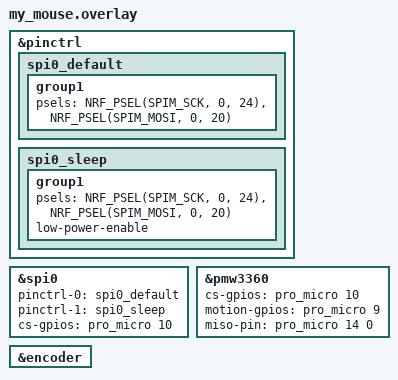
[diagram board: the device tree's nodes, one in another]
#include <dt-bindings/zmk/matrix_transform.h>

&pinctrl {
    spi0_default: spi0_default {
        group1 {
            // D5 (SCK) and D3 (MOSI)
            psels = <NRF_PSEL(SPIM_SCK, 0, 24)>, <NRF_PSEL(SPIM_MOSI, 0, 20)>;
        };
    };

    spi0_sleep: spi0_sleep {
        group1 {
            psels = <NRF_PSEL(SPIM_SCK, 0, 24)>, <NRF_PSEL(SPIM_MOSI, 0, 20)>;
            low-power-enable;
        };
    };
};

&spi0 {
    status = "okay";
    pinctrl-0 = <&spi0_default>;
    pinctrl-1 = <&spi0_sleep>;
    pinctrl-names = "default", "sleep";
    cs-gpios = <&pro_micro 10 0>; // Use D6 (P1.00) as CS
};

&pmw3360 {
    status = "okay";
    cs-gpios = <&pro_micro 10 0>; // Use D6 (P1.00) as CS
    motion-gpios = <&pro_micro 9 0>; // Use D7 (P0.11) as MOTION
    miso-pin = <&pro_micro 14 0>; // Use D4 (P0.22) as MISO
};

&encoder {
    status = "okay";
};
